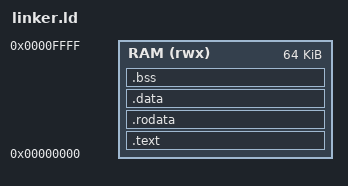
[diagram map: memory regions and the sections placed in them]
/* One flat 64 KB RAM. Code starts at 0, stack grows down from the top. */
OUTPUT_ARCH("riscv")
ENTRY(_start)

MEMORY
{
    RAM (rwx) : ORIGIN = 0x00000000, LENGTH = 64K
}

SECTIONS
{
    .text : {
        *(.text.init)          /* _start goes first so it lands at address 0 */
        *(.text .text.*)
    } > RAM

    .rodata : ALIGN(4) {
        *(.rodata .rodata.* .srodata .srodata.*)
    } > RAM

    .data : ALIGN(4) {
        *(.data .data.* .sdata .sdata.*)
    } > RAM

    .bss (NOLOAD) : ALIGN(4) {
        __bss_start = .;
        *(.bss .bss.* .sbss .sbss.* COMMON)
        . = ALIGN(4);
        __bss_end = .;
    } > RAM

    _end = .;
    __stack_top = ORIGIN(RAM) + LENGTH(RAM);
}
